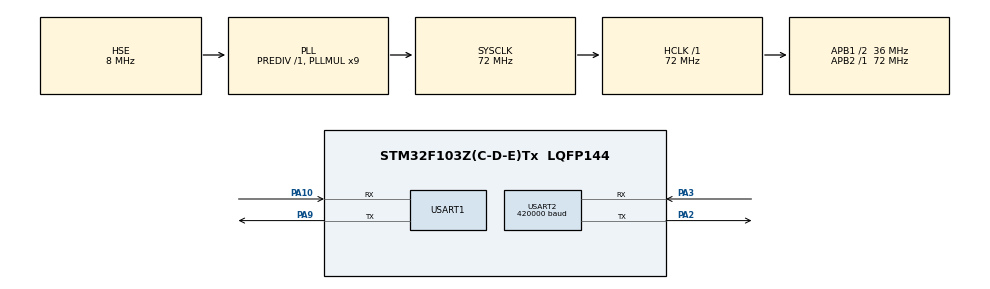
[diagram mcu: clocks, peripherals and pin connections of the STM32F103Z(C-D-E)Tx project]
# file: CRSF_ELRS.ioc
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Mcu.Family=STM32F1
Mcu.Name=STM32F103Z(C-D-E)Tx
Mcu.Package=LQFP144
NVIC.PriorityGroup=NVIC_PRIORITYGROUP_4
NVIC.USART1_IRQn=true\:0\:0\:false\:false\:true\:true\:true
NVIC.USART2_IRQn=true\:0\:0\:false\:false\:true\:true\:true
OSC_IN.Mode=HSE-External-Oscillator
OSC_IN.Signal=RCC_OSC_IN
OSC_OUT.Mode=HSE-External-Oscillator
OSC_OUT.Signal=RCC_OSC_OUT
PA10.Mode=Asynchronous
PA10.Signal=USART1_RX
PA2.Mode=Asynchronous
PA2.Signal=USART2_TX
PA3.Mode=Asynchronous
PA3.Signal=USART2_RX
PA9.Mode=Asynchronous
PA9.Signal=USART1_TX
ProjectManager.HeapSize=0x200
ProjectManager.StackSize=0x400
ProjectManager.TargetToolchain=MDK-ARM V5.32
RCC.AHBFreq_Value=72000000
RCC.APB1CLKDivider=RCC_HCLK_DIV2
RCC.APB1Freq_Value=36000000
RCC.APB1TimFreq_Value=72000000
RCC.APB2Freq_Value=72000000
RCC.APB2TimFreq_Value=72000000
RCC.HCLKFreq_Value=72000000
RCC.PLLMUL=RCC_PLL_MUL9
RCC.PLLSourceVirtual=RCC_PLLSOURCE_HSE
RCC.SYSCLKFreq_VALUE=72000000
RCC.SYSCLKSource=RCC_SYSCLKSOURCE_PLLCLK
RCC.USBFreq_Value=72000000
USART1.VirtualMode=VM_ASYNC
USART2.BaudRate=420000
USART2.VirtualMode=VM_ASYNC
VP_SYS_VS_ND.Mode=No_Debug
board=custom

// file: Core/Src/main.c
/* USER CODE BEGIN Header */
/**
  ******************************************************************************
  * @file           : main.c
  * @brief          : Main program body
  ******************************************************************************
  * @attention
  *
  * <h2><center>&copy; Copyright (c) 2023 STMicroelectronics.
  * All rights reserved.</center></h2>
  *
  * This software component is licensed by ST under BSD 3-Clause license,
  * the "License"; You may not use this file except in compliance with the
  * License. You may obtain a copy of the License at:
  *                        opensource.org/licenses/BSD-3-Clause
  *
  ******************************************************************************
  */
/* USER CODE END Header */
#include "main.h"
#include "usart.h"
#include "gpio.h"

/* USER CODE BEGIN PV */
//extern uint16_t CRSF_CH[17];
extern int CrsfChannels[CRSF_NUM_CHANNELS];
/* USER CODE END PV */

void SystemClock_Config(void);

int main(void)
{

  /* MCU Configuration--------------------------------------------------------*/

  /* Reset of all peripherals, Initializes the Flash interface and the Systick. */
  HAL_Init();

  /* USER CODE BEGIN Init */
	Crc_init(0xD5);
  /* USER CODE END Init */

  /* Configure the system clock */
  SystemClock_Config();

  /* Initialize all configured peripherals */
  MX_GPIO_Init();
  MX_USART1_UART_Init();
  MX_USART2_UART_Init();
  /* USER CODE BEGIN 2 */

	HAL_UART_Receive_IT(&huart2, (uint8_t *)RxBuffer,LENGTH);
  /* USER CODE END 2 */

  /* Infinite loop */
  while (1)
  {

//    /* USER CODE BEGIN 3 */

			printf("ch1:%d\r\n",CrsfChannels[0]);
			printf("ch2:%d\r\n",CrsfChannels[1]);
			printf("ch3:%d\r\n",CrsfChannels[2]);
			printf("ch4:%d\r\n",CrsfChannels[3]);
			printf("ch5:%d\r\n",CrsfChannels[4]);
			printf("ch6:%d\r\n",CrsfChannels[5]);
			printf("ch7:%d\r\n",CrsfChannels[6]);
			printf("ch8:%d\r\n",CrsfChannels[7]);
			printf("ch9:%d\r\n",CrsfChannels[8]);
			printf("ch10:%d\r\n",CrsfChannels[9]);
			printf("ch11:%d\r\n",CrsfChannels[10]);
			printf("ch12:%d\r\n",CrsfChannels[11]);
			HAL_Delay(100);

  }
  /* USER CODE END 3 */
}

void SystemClock_Config(void)
{
  RCC_OscInitTypeDef RCC_OscInitStruct = {0};
  RCC_ClkInitTypeDef RCC_ClkInitStruct = {0};

  /** Initializes the RCC Oscillators according to the specified parameters
  * in the RCC_OscInitTypeDef structure.
  */
  RCC_OscInitStruct.OscillatorType = RCC_OSCILLATORTYPE_HSE;
  RCC_OscInitStruct.HSEState = RCC_HSE_ON;
  RCC_OscInitStruct.HSEPredivValue = RCC_HSE_PREDIV_DIV1;
  RCC_OscInitStruct.HSIState = RCC_HSI_ON;
  RCC_OscInitStruct.PLL.PLLState = RCC_PLL_ON;
  RCC_OscInitStruct.PLL.PLLSource = RCC_PLLSOURCE_HSE;
  RCC_OscInitStruct.PLL.PLLMUL = RCC_PLL_MUL9;
  if (HAL_RCC_OscConfig(&RCC_OscInitStruct) != HAL_OK)
  {
    Error_Handler();
  }
  /** Initializes the CPU, AHB and APB buses clocks
  */
  RCC_ClkInitStruct.ClockType = RCC_CLOCKTYPE_HCLK|RCC_CLOCKTYPE_SYSCLK
                              |RCC_CLOCKTYPE_PCLK1|RCC_CLOCKTYPE_PCLK2;
  RCC_ClkInitStruct.SYSCLKSource = RCC_SYSCLKSOURCE_PLLCLK;
  RCC_ClkInitStruct.AHBCLKDivider = RCC_SYSCLK_DIV1;
  RCC_ClkInitStruct.APB1CLKDivider = RCC_HCLK_DIV2;
  RCC_ClkInitStruct.APB2CLKDivider = RCC_HCLK_DIV1;

  if (HAL_RCC_ClockConfig(&RCC_ClkInitStruct, FLASH_LATENCY_2) != HAL_OK)
  {
    Error_Handler();
  }
}

void Error_Handler(void)
{
  __disable_irq();
  while (1)
  {
  }
}

/************************ (C) COPYRIGHT STMicroelectronics *****END OF FILE****/
